# ATSAM3S4B register map
Vendor: Atmel; File version: 0
CPU: CM3 r2p0, selectable endian, no MPU, no FPU, 0x4 interrupt priority bits, 0x0 interrupts
Registers are 32-bit, read-write, no defined reset value unless marked. A register's access mark holds for its fields unless they carry their own. Offsets are from the block's base; [hi:lo] are bit positions; {n}, {i} and the like mark numbered series; 'fields as' and 'values as' point back to an identical list.

## CRCCU — Cyclic Redundancy Check Calculation Unit
Base 0x40044000; register names take the prefix CRCCU_
0x00 DSCR reset 0x0 — CRCCU Descriptor Base Register
  [31:9] DSCR — Descriptor Base Address
0x08 DMA_EN wo reset 0x0 — CRCCU DMA Enable Register
  [0] DMAEN — DMA Enable Register
0x0C DMA_DIS wo reset 0x0 — CRCCU DMA Disable Register
  [0] DMADIS — DMA Disable Register
0x10 DMA_SR ro reset 0x0 — CRCCU DMA Status Register
  [0] DMASR — DMA Status Register
0x14 DMA_IER wo reset 0x0 — CRCCU DMA Interrupt Enable Register
  [0] DMAIER — Interrupt Enable register
0x18 DMA_IDR wo reset 0x0 — CRCCU DMA Interrupt Disable Register
  [0] DMAIDR — Interrupt Disable register
0x1C DMA_IMR ro reset 0x0 — CRCCU DMA Interrupt Mask Register
  [0] DMAIMR — Interrupt Mask Register
0x20 DMA_ISR ro reset 0x0 — CRCCU DMA Interrupt Status Register
  [0] DMAISR — Interrupt Status register
0x34 CR wo reset 0x0 — CRCCU Control Register
  [0] RESET — CRC Computation Reset
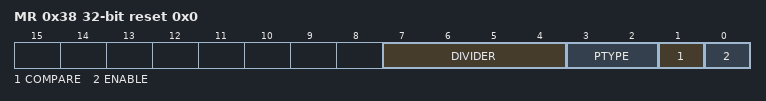
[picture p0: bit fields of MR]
0x38 MR reset 0x0 — CRCCU Mode Register
  [7:4] DIVIDER — Request Divider
  [3:2] PTYPE — Primitive Polynomial
    0=CCITT8023 (Polynom 0x04C11DB7); 1=CASTAGNOLI (Polynom 0x1EDC6F41); 2=CCITT16 (Polynom 0x1021)
  [1] COMPARE — CRC Compare
  [0] ENABLE — CRC Enable
0x3C SR ro reset 0xFFFFFFFF — CRCCU Status Register
  [31:0] CRC — Cyclic Redundancy Check Value
0x40 IER wo reset 0x0 — CRCCU Interrupt Enable Register
  [0] ERRIER — CRC Error Interrupt Enable
0x44 IDR wo reset 0x0 — CRCCU Interrupt Disable Register
  [0] ERRIDR — CRC Error Interrupt Disable
0x48 IMR ro reset 0x0 — CRCCU Interrupt Mask Register
  [0] ERRIMR — CRC Error Interrupt Mask
0x4C ISR ro reset 0x0 — CRCCU Interrupt Status Register
  [0] ERRISR — CRC Error Interrupt Status

## MATRIX — AHB Bus Matrix
Base 0x400E0200
{0x0+4i} MATRIX_MCFG[{i}] (i=0..3) — Master Configuration Register
  [2:0] ULBT — Undefined Length Burst Type
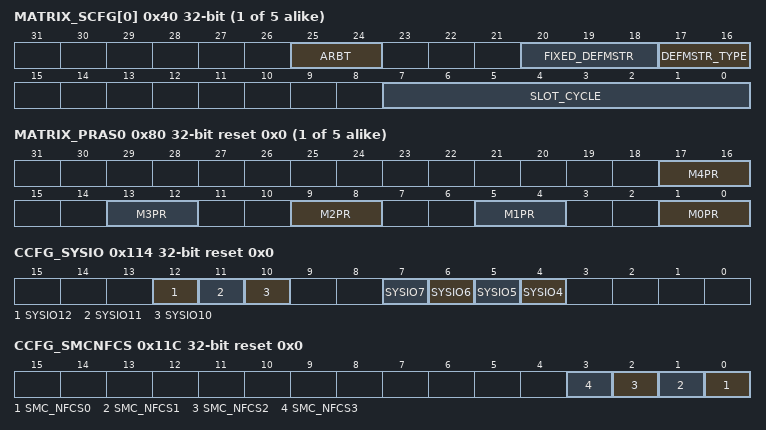
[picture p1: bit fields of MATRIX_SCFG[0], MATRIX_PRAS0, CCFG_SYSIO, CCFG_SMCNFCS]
{0x40+4i} MATRIX_SCFG[{i}] (i=0..4) — Slave Configuration Register
  [25:24] ARBT — Arbitration Type
  [20:18] FIXED_DEFMSTR — Fixed Default Master
  [17:16] DEFMSTR_TYPE — Default Master Type
  [7:0] SLOT_CYCLE — Maximum Number of Allowed Cycles for a Burst
{0x80+8i} MATRIX_PRAS{i} reset 0x0 (i=0..4) — Priority Register A for Slave {i}
  [4n+1:4n] M{n}PR (n=0..4) — Master {n} Priority
0x114 CCFG_SYSIO reset 0x0 — System I/O Configuration register
  [12] SYSIO12 — PB12 or ERASE Assignment
  [11] SYSIO11 — PB11 or DDP Assignment
  [10] SYSIO10 — PB10 or DDM Assignment
  [7] SYSIO7 — PB7 or TCK/SWCLK Assignment
  [6] SYSIO6 — PB6 or TMS/SWDIO Assignment
  [5] SYSIO5 — PB5 or TDO/TRACESWO Assignment
  [4] SYSIO4 — PB4 or TDI Assignment
0x11C CCFG_SMCNFCS reset 0x0 — SMC Chip Select NAND Flash Assignment Register
  [n] SMC_NFCS{n} (n=0..3) — SMC NAND Flash Chip Select {n} Assignment
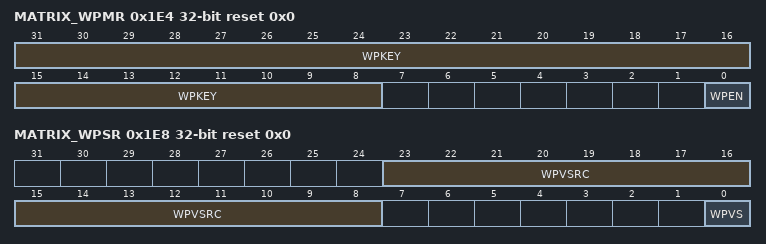
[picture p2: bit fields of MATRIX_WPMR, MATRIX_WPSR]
0x1E4 MATRIX_WPMR reset 0x0 — Write Protect Mode Register
  [31:8] WPKEY — Write Protect KEY (Write-only)
  [0] WPEN — Write Protect ENable
0x1E8 MATRIX_WPSR ro reset 0x0 — Write Protect Status Register
  [23:8] WPVSRC — Write Protect Violation Source
  [0] WPVS — Write Protect Violation Status

## CHIPID — Chip Identifier
Base 0x400E0740; register names take the prefix CHIPID_
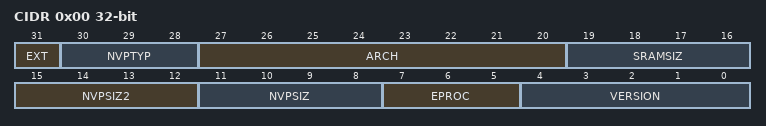
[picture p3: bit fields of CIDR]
0x00 CIDR ro — Chip ID Register
  [31] EXT — Extension Flag
  [30:28] NVPTYP — Nonvolatile Program Memory Type
    0=ROM; 1=ROMLESS (ROMless or on-chip Flash); 2=FLASH (Embedded Flash Memory); 3=ROM_FLASH (ROM and Embedded Flash Memory- NVPSIZ is ROM size- NVPSIZ2 is Flash size); 4=SRAM (SRAM emulating ROM)
  [27:20] ARCH — Architecture Identifier
    25=AT91SAM9xx Series; 41=AT91SAM9XExx Series; 52=AT91x34 Series; 55=CAP7 (CAP7 Series); 57=CAP9 (CAP9 Series); 59=CAP11 (CAP11 Series); 64=AT91x40 Series; 66=AT91x42 Series; 69=AT91SAM4SH2 (AT91SAM4SH2 Series); 85=AT91x55 Series; 96=AT91SAM7Axx Series; 97=AT91SAM7AQxx Series; 99=AT91x63 Series; 100=SAM4CxxC (SAM4CxC Series (100-pin version)); 112=AT91SAM7Sxx Series; 113=AT91SAM7XCxx Series; 114=AT91SAM7SExx Series; 115=AT91SAM7Lxx Series; 117=AT91SAM7Xxx Series; 118=AT91SAM7SLxx Series; 128=SAM3UxC Series (100-pin version); 129=SAM3UxE Series (144-pin version); 131=SAM3AxC Series (100-pin version); 132=SAM3XxC Series (100-pin version); 133=SAM3XxE Series (144-pin version); 134=SAM3XxG Series (208/217-pin version); 136=SAM3SxASeries (48-pin version); 137=SAM3SxB Series (64-pin version); 138=SAM3SxC Series (100-pin version); 146=AT91x92 Series; 153=SAM3SDxB Series (64-pin version); 154=SAM3SDxC Series (100-pin version); 165=SAM5A; 176=SAM4LxA Series (48-pin version); 177=SAM4LxB Series (64-pin version); 178=SAM4LxC Series (100-pin version); 240=AT75Cxx Series
  [19:16] SRAMSIZ — Internal SRAM Size
    0=48K (48 Kbytes); 1=192K (192 Kbytes); 2=2K (2 Kbytes); 3=6K (6 Kbytes); 4=24K (24 Kbytes); 5=4K (4 Kbytes); 6=80K (80 Kbytes); 7=160K (160 Kbytes); 8=8K (8 Kbytes); 9=16K (16 Kbytes); 10=32K (32 Kbytes); 11=64K (64 Kbytes); 12=128K (128 Kbytes); 13=256K (256 Kbytes); 14=96K (96 Kbytes); 15=512K (512 Kbytes)
  [15:12] NVPSIZ2 — Second Nonvolatile Program Memory Size
    0=NONE; 1=8K (8 Kbytes); 2=16K (16 Kbytes); 3=32K (32 Kbytes); 5=64K (64 Kbytes); 7=128K (128 Kbytes); 9=256K (256 Kbytes); 10=512K (512 Kbytes); 12=1024K (1024 Kbytes); 14=2048K (2048 Kbytes)
  [11:8] NVPSIZ — Nonvolatile Program Memory Size
    values as NVPSIZ2
  [7:5] EPROC — Embedded Processor
    1=ARM946ES; 2=ARM7TDMI; 3=CM3 (Cortex-M3); 4=ARM920T; 5=ARM926EJS; 6=CA5 (Cortex-A5); 7=CM4 (Cortex-M4)
  [4:0] VERSION — Version of the Device
0x04 EXID ro — Chip ID Extension Register
  [31:0] EXID — Chip ID Extension
